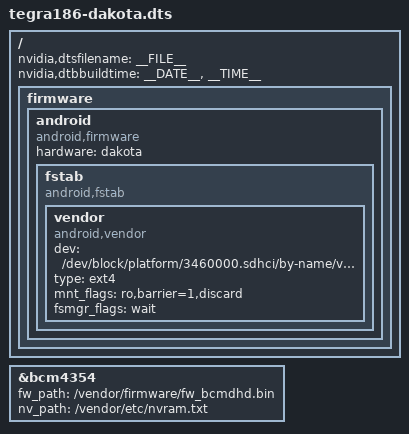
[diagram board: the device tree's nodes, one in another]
/*
 * tegra186-dakota.dts tegra186 dakota device
 *
 * Copyright (c) 2016-2017, NVIDIA CORPORATION. All rights reserved.
 * Copyright (c)      2018, Codefire Solutions. All rights reserved.
 *
 * This program is free software; you can redistribute it and/or modify
 * it under the terms of the GNU General Public License as published by
 * the Free Software Foundation; version 2 of the License.
 *
 * This program is distributed in the hope that it will be useful, but WITHOUT
 * ANY WARRANTY; without even the implied warranty of MERCHANTABILITY or
 * FITNESS FOR A PARTICULAR PURPOSE.  See the GNU General Public License for
 * more details.
 */

#include "tegra186-quill-p3310-1000-c03-00-base.dts"

/ {
	nvidia,dtsfilename = __FILE__;
	nvidia,dtbbuildtime = __DATE__, __TIME__;

	firmware: firmware {
		android {
			compatible = "android,firmware";
			hardware = "dakota";
			fstab {
				compatible = "android,fstab";
				vendor {
					compatible = "android,vendor";
					dev = "/dev/block/platform/3460000.sdhci/by-name/vendor";
					type = "ext4";
					mnt_flags = "ro,barrier=1,discard";
					fsmgr_flags = "wait";
					status = "ok";
				};
			};
		};
	};
};

/delete-node/ &bcm4359;

&bcm4354 {
	fw_path = "/vendor/firmware/fw_bcmdhd.bin";
	nv_path = "/vendor/etc/nvram.txt";
};
